AUTOSAR XML (schema 4-0-3)
standard types defined: Boolean, UInt16
package /AUTOSAR_Platform/DataConstrs
  range DC_Boolean: raw 0..1
  range DC_UInt16: raw 0..65535
package /PATAC/MSM/ComponentTypes
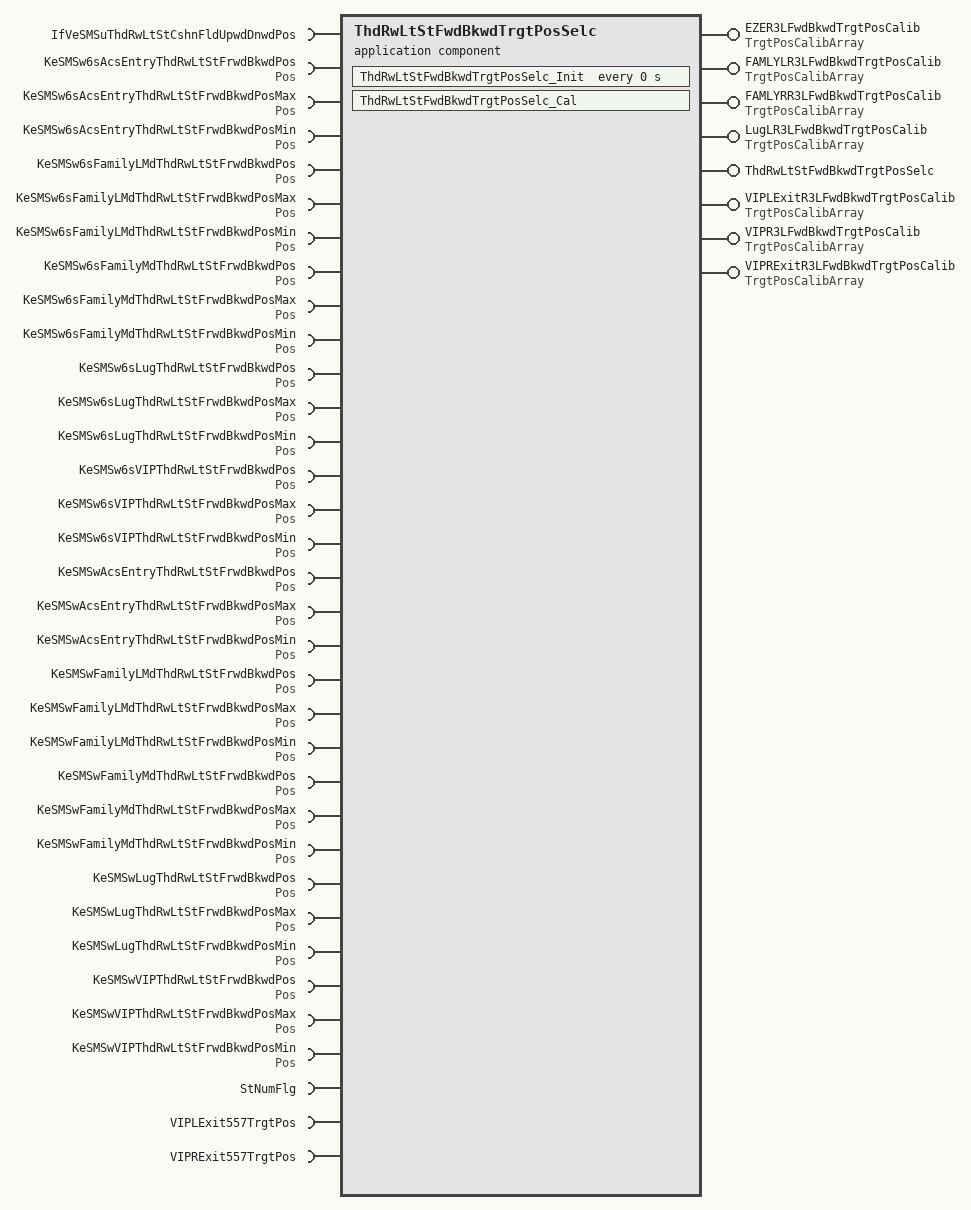
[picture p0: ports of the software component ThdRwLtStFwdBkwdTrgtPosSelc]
  application sw component type ThdRwLtStFwdBkwdTrgtPosSelc
    8 x provide port:
      EZER3LFwdBkwdTrgtPosCalib: nonqueued-sender-com-spec{data-element=TrgtPosArray, init-value=[4095, 4095, 4095]}, provided-interface=TrgtPosCalibArray
      FAMLYLR3LFwdBkwdTrgtPosCalib: nonqueued-sender-com-spec{data-element=TrgtPosArray, init-value=[4095, 4095, 4095]}, provided-interface=TrgtPosCalibArray
      FAMLYRR3LFwdBkwdTrgtPosCalib: nonqueued-sender-com-spec{data-element=TrgtPosArray, init-value=[4095, 4095, 4095]}, provided-interface=TrgtPosCalibArray
      LugLR3LFwdBkwdTrgtPosCalib: nonqueued-sender-com-spec{data-element=TrgtPosArray, init-value=[4095, 4095, 4095]}, provided-interface=TrgtPosCalibArray
      ThdRwLtStFwdBkwdTrgtPosSelc: server-com-spec{operation=Cal, queue-length=1}, provided-interface=ThdRwLtStFwdBkwdTrgtPosSelc
      VIPLExitR3LFwdBkwdTrgtPosCalib: nonqueued-sender-com-spec{data-element=TrgtPosArray, init-value=[4095, 4095, 4095]}, provided-interface=TrgtPosCalibArray
      VIPR3LFwdBkwdTrgtPosCalib: nonqueued-sender-com-spec{data-element=TrgtPosArray, init-value=[4095, 4095, 4095]}, provided-interface=TrgtPosCalibArray
      VIPRExitR3LFwdBkwdTrgtPosCalib: nonqueued-sender-com-spec{data-element=TrgtPosArray, init-value=[4095, 4095, 4095]}, provided-interface=TrgtPosCalibArray
    34 x require port:
      IfVeSMSuThdRwLtStCshnFldUpwdDnwdPos: nonqueued-receiver-com-spec{data-element=Val, filter=data-filter-type=ALWAYS, init-value=0}, required-interface=IfVeSMSuThdRwLtStCshnFldUpwdDnwdPos
      KeSMSw6sAcsEntryThdRwLtStFrwdBkwdPos: parameter-require-com-spec{init-value=2760, parameter=Val}, required-interface=Pos
      KeSMSw6sAcsEntryThdRwLtStFrwdBkwdPosMax: parameter-require-com-spec{init-value=4000, parameter=Val}, required-interface=Pos
      KeSMSw6sAcsEntryThdRwLtStFrwdBkwdPosMin: parameter-require-com-spec{init-value=2760, parameter=Val}, required-interface=Pos
      KeSMSw6sFamilyLMdThdRwLtStFrwdBkwdPos: parameter-require-com-spec{init-value=0, parameter=Val}, required-interface=Pos
      KeSMSw6sFamilyLMdThdRwLtStFrwdBkwdPosMax: parameter-require-com-spec{init-value=0, parameter=Val}, required-interface=Pos
      KeSMSw6sFamilyLMdThdRwLtStFrwdBkwdPosMin: parameter-require-com-spec{init-value=0, parameter=Val}, required-interface=Pos
      KeSMSw6sFamilyMdThdRwLtStFrwdBkwdPos: parameter-require-com-spec{init-value=0, parameter=Val}, required-interface=Pos
      KeSMSw6sFamilyMdThdRwLtStFrwdBkwdPosMax: parameter-require-com-spec{init-value=0, parameter=Val}, required-interface=Pos
      KeSMSw6sFamilyMdThdRwLtStFrwdBkwdPosMin: parameter-require-com-spec{init-value=0, parameter=Val}, required-interface=Pos
      KeSMSw6sLugThdRwLtStFrwdBkwdPos: parameter-require-com-spec{init-value=30, parameter=Val}, required-interface=Pos
      KeSMSw6sLugThdRwLtStFrwdBkwdPosMax: parameter-require-com-spec{init-value=40, parameter=Val}, required-interface=Pos
      KeSMSw6sLugThdRwLtStFrwdBkwdPosMin: parameter-require-com-spec{init-value=20, parameter=Val}, required-interface=Pos
      KeSMSw6sVIPThdRwLtStFrwdBkwdPos: parameter-require-com-spec{init-value=4000, parameter=Val}, required-interface=Pos
      KeSMSw6sVIPThdRwLtStFrwdBkwdPosMax: parameter-require-com-spec{init-value=4000, parameter=Val}, required-interface=Pos
      KeSMSw6sVIPThdRwLtStFrwdBkwdPosMin: parameter-require-com-spec{init-value=4000, parameter=Val}, required-interface=Pos
      KeSMSwAcsEntryThdRwLtStFrwdBkwdPos: parameter-require-com-spec{init-value=2760, parameter=Val}, required-interface=Pos
      KeSMSwAcsEntryThdRwLtStFrwdBkwdPosMax: parameter-require-com-spec{init-value=4000, parameter=Val}, required-interface=Pos
      KeSMSwAcsEntryThdRwLtStFrwdBkwdPosMin: parameter-require-com-spec{init-value=2760, parameter=Val}, required-interface=Pos
      KeSMSwFamilyLMdThdRwLtStFrwdBkwdPos: parameter-require-com-spec{init-value=0, parameter=Val}, required-interface=Pos
      KeSMSwFamilyLMdThdRwLtStFrwdBkwdPosMax: parameter-require-com-spec{init-value=0, parameter=Val}, required-interface=Pos
      KeSMSwFamilyLMdThdRwLtStFrwdBkwdPosMin: parameter-require-com-spec{init-value=0, parameter=Val}, required-interface=Pos
      KeSMSwFamilyMdThdRwLtStFrwdBkwdPos: parameter-require-com-spec{init-value=0, parameter=Val}, required-interface=Pos
      KeSMSwFamilyMdThdRwLtStFrwdBkwdPosMax: parameter-require-com-spec{init-value=0, parameter=Val}, required-interface=Pos
      KeSMSwFamilyMdThdRwLtStFrwdBkwdPosMin: parameter-require-com-spec{init-value=0, parameter=Val}, required-interface=Pos
      KeSMSwLugThdRwLtStFrwdBkwdPos: parameter-require-com-spec{init-value=30, parameter=Val}, required-interface=Pos
      KeSMSwLugThdRwLtStFrwdBkwdPosMax: parameter-require-com-spec{init-value=40, parameter=Val}, required-interface=Pos
      KeSMSwLugThdRwLtStFrwdBkwdPosMin: parameter-require-com-spec{init-value=20, parameter=Val}, required-interface=Pos
      KeSMSwVIPThdRwLtStFrwdBkwdPos: parameter-require-com-spec{init-value=4000, parameter=Val}, required-interface=Pos
      KeSMSwVIPThdRwLtStFrwdBkwdPosMax: parameter-require-com-spec{init-value=4000, parameter=Val}, required-interface=Pos
      KeSMSwVIPThdRwLtStFrwdBkwdPosMin: parameter-require-com-spec{init-value=4000, parameter=Val}, required-interface=Pos
      StNumFlg: required-interface=StNumFlg
        required-com-specs:
          data-element=Is4s, filter=data-filter-type=ALWAYS, init-value=0
          data-element=Is6s, filter=data-filter-type=ALWAYS, init-value=0
          data-element=Is6s7s, filter=data-filter-type=ALWAYS, init-value=0
          data-element=Is7s, filter=data-filter-type=ALWAYS, init-value=0
      VIPLExit557TrgtPos: required-com-specs=[VIPLExit557TrgtPos/Get, VIPLExit557TrgtPos/Set], required-interface=VIPLExit557TrgtPos
      VIPRExit557TrgtPos: required-com-specs=[VIPRExit557TrgtPos/Get, VIPRExit557TrgtPos/Set], required-interface=VIPRExit557TrgtPos
    behavior ThdRwLtStFwdBkwdTrgtPosSelc_InternalBehavior
      operation invoked event OIT_ThdRwLtStFwdBkwdTrgtPosSelc_Cal_ThdRwLtStFwdBkwdTrgtPosSelc_Cal: start-on-event=ThdRwLtStFwdBkwdTrgtPosSelc_Cal, operation=ThdRwLtStFwdBkwdTrgtPosSelc.Cal
      timing event ThdRwLtStFwdBkwdTrgtPosSelc_InitEvent: start-on-event=ThdRwLtStFwdBkwdTrgtPosSelc_Init, period=0
      runnable ThdRwLtStFwdBkwdTrgtPosSelc_Cal
        data-receive-point-by-arguments:
          5 x access:
            REC_IfVeSMSuThdRwLtStCshnFldUpwdDnwdPos_Val: accessed-variable=IfVeSMSuThdRwLtStCshnFldUpwdDnwdPos.Val
            REC_StNumFlg_Is4s: accessed-variable=StNumFlg.Is4s
            REC_StNumFlg_Is6s: accessed-variable=StNumFlg.Is6s
            REC_StNumFlg_Is6s7s: accessed-variable=StNumFlg.Is6s7s
            REC_StNumFlg_Is7s: accessed-variable=StNumFlg.Is7s
        data-send-points:
          7 x access:
            SEND_EZER3LFwdBkwdTrgtPosCalib_TrgtPosArray: accessed-variable=EZER3LFwdBkwdTrgtPosCalib.TrgtPosArray
            SEND_FAMLYLR3LFwdBkwdTrgtPosCalib_TrgtPosArray: accessed-variable=FAMLYLR3LFwdBkwdTrgtPosCalib.TrgtPosArray
            SEND_FAMLYRR3LFwdBkwdTrgtPosCalib_TrgtPosArray: accessed-variable=FAMLYRR3LFwdBkwdTrgtPosCalib.TrgtPosArray
            SEND_LugLR3LFwdBkwdTrgtPosCalib_TrgtPosArray: accessed-variable=LugLR3LFwdBkwdTrgtPosCalib.TrgtPosArray
            SEND_VIPLExitR3LFwdBkwdTrgtPosCalib_TrgtPosArray: accessed-variable=VIPLExitR3LFwdBkwdTrgtPosCalib.TrgtPosArray
            SEND_VIPR3LFwdBkwdTrgtPosCalib_TrgtPosArray: accessed-variable=VIPR3LFwdBkwdTrgtPosCalib.TrgtPosArray
            SEND_VIPRExitR3LFwdBkwdTrgtPosCalib_TrgtPosArray: accessed-variable=VIPRExitR3LFwdBkwdTrgtPosCalib.TrgtPosArray
        30 x parameter access:
          PA_KeSMSw6sAcsEntryThdRwLtStFrwdBkwdPos_Val: accessed-parameter=KeSMSw6sAcsEntryThdRwLtStFrwdBkwdPos.Val
          PA_KeSMSw6sAcsEntryThdRwLtStFrwdBkwdPosMax_Val: accessed-parameter=KeSMSw6sAcsEntryThdRwLtStFrwdBkwdPosMax.Val
          PA_KeSMSw6sAcsEntryThdRwLtStFrwdBkwdPosMin_Val: accessed-parameter=KeSMSw6sAcsEntryThdRwLtStFrwdBkwdPosMin.Val
          PA_KeSMSw6sFamilyLMdThdRwLtStFrwdBkwdPos_Val: accessed-parameter=KeSMSw6sFamilyLMdThdRwLtStFrwdBkwdPos.Val
          PA_KeSMSw6sFamilyLMdThdRwLtStFrwdBkwdPosMax_Val: accessed-parameter=KeSMSw6sFamilyLMdThdRwLtStFrwdBkwdPosMax.Val
          PA_KeSMSw6sFamilyLMdThdRwLtStFrwdBkwdPosMin_Val: accessed-parameter=KeSMSw6sFamilyLMdThdRwLtStFrwdBkwdPosMin.Val
          PA_KeSMSw6sFamilyMdThdRwLtStFrwdBkwdPos_Val: accessed-parameter=KeSMSw6sFamilyMdThdRwLtStFrwdBkwdPos.Val
          PA_KeSMSw6sFamilyMdThdRwLtStFrwdBkwdPosMax_Val: accessed-parameter=KeSMSw6sFamilyMdThdRwLtStFrwdBkwdPosMax.Val
          PA_KeSMSw6sFamilyMdThdRwLtStFrwdBkwdPosMin_Val: accessed-parameter=KeSMSw6sFamilyMdThdRwLtStFrwdBkwdPosMin.Val
          PA_KeSMSw6sLugThdRwLtStFrwdBkwdPos_Val: accessed-parameter=KeSMSw6sLugThdRwLtStFrwdBkwdPos.Val
          PA_KeSMSw6sLugThdRwLtStFrwdBkwdPosMax_Val: accessed-parameter=KeSMSw6sLugThdRwLtStFrwdBkwdPosMax.Val
          PA_KeSMSw6sLugThdRwLtStFrwdBkwdPosMin_Val: accessed-parameter=KeSMSw6sLugThdRwLtStFrwdBkwdPosMin.Val
          PA_KeSMSw6sVIPThdRwLtStFrwdBkwdPos_Val: accessed-parameter=KeSMSw6sVIPThdRwLtStFrwdBkwdPos.Val
          PA_KeSMSw6sVIPThdRwLtStFrwdBkwdPosMax_Val: accessed-parameter=KeSMSw6sVIPThdRwLtStFrwdBkwdPosMax.Val
          PA_KeSMSw6sVIPThdRwLtStFrwdBkwdPosMin_Val: accessed-parameter=KeSMSw6sVIPThdRwLtStFrwdBkwdPosMin.Val
          PA_KeSMSwAcsEntryThdRwLtStFrwdBkwdPos_Val: accessed-parameter=KeSMSwAcsEntryThdRwLtStFrwdBkwdPos.Val
          PA_KeSMSwAcsEntryThdRwLtStFrwdBkwdPosMax_Val: accessed-parameter=KeSMSwAcsEntryThdRwLtStFrwdBkwdPosMax.Val
          PA_KeSMSwAcsEntryThdRwLtStFrwdBkwdPosMin_Val: accessed-parameter=KeSMSwAcsEntryThdRwLtStFrwdBkwdPosMin.Val
          PA_KeSMSwFamilyLMdThdRwLtStFrwdBkwdPos_Val: accessed-parameter=KeSMSwFamilyLMdThdRwLtStFrwdBkwdPos.Val
          PA_KeSMSwFamilyLMdThdRwLtStFrwdBkwdPosMax_Val: accessed-parameter=KeSMSwFamilyLMdThdRwLtStFrwdBkwdPosMax.Val
          PA_KeSMSwFamilyLMdThdRwLtStFrwdBkwdPosMin_Val: accessed-parameter=KeSMSwFamilyLMdThdRwLtStFrwdBkwdPosMin.Val
          PA_KeSMSwFamilyMdThdRwLtStFrwdBkwdPos_Val: accessed-parameter=KeSMSwFamilyMdThdRwLtStFrwdBkwdPos.Val
          PA_KeSMSwFamilyMdThdRwLtStFrwdBkwdPosMax_Val: accessed-parameter=KeSMSwFamilyMdThdRwLtStFrwdBkwdPosMax.Val
          PA_KeSMSwFamilyMdThdRwLtStFrwdBkwdPosMin_Val: accessed-parameter=KeSMSwFamilyMdThdRwLtStFrwdBkwdPosMin.Val
          PA_KeSMSwLugThdRwLtStFrwdBkwdPos_Val: accessed-parameter=KeSMSwLugThdRwLtStFrwdBkwdPos.Val
          PA_KeSMSwLugThdRwLtStFrwdBkwdPosMax_Val: accessed-parameter=KeSMSwLugThdRwLtStFrwdBkwdPosMax.Val
          PA_KeSMSwLugThdRwLtStFrwdBkwdPosMin_Val: accessed-parameter=KeSMSwLugThdRwLtStFrwdBkwdPosMin.Val
          PA_KeSMSwVIPThdRwLtStFrwdBkwdPos_Val: accessed-parameter=KeSMSwVIPThdRwLtStFrwdBkwdPos.Val
          PA_KeSMSwVIPThdRwLtStFrwdBkwdPosMax_Val: accessed-parameter=KeSMSwVIPThdRwLtStFrwdBkwdPosMax.Val
          PA_KeSMSwVIPThdRwLtStFrwdBkwdPosMin_Val: accessed-parameter=KeSMSwVIPThdRwLtStFrwdBkwdPosMin.Val
        sync call SC_VIPLExit557TrgtPos_Get: operation=VIPLExit557TrgtPos.Get, timeout=0
        sync call SC_VIPRExit557TrgtPos_Get: operation=VIPRExit557TrgtPos.Get, timeout=0
      runnable ThdRwLtStFwdBkwdTrgtPosSelc_Init
        30 x parameter access:
          PA_KeSMSw6sAcsEntryThdRwLtStFrwdBkwdPos_Val: accessed-parameter=KeSMSw6sAcsEntryThdRwLtStFrwdBkwdPos.Val
          PA_KeSMSw6sAcsEntryThdRwLtStFrwdBkwdPosMax_Val: accessed-parameter=KeSMSw6sAcsEntryThdRwLtStFrwdBkwdPosMax.Val
          PA_KeSMSw6sAcsEntryThdRwLtStFrwdBkwdPosMin_Val: accessed-parameter=KeSMSw6sAcsEntryThdRwLtStFrwdBkwdPosMin.Val
          PA_KeSMSw6sFamilyLMdThdRwLtStFrwdBkwdPos_Val: accessed-parameter=KeSMSw6sFamilyLMdThdRwLtStFrwdBkwdPos.Val
          PA_KeSMSw6sFamilyLMdThdRwLtStFrwdBkwdPosMax_Val: accessed-parameter=KeSMSw6sFamilyLMdThdRwLtStFrwdBkwdPosMax.Val
          PA_KeSMSw6sFamilyLMdThdRwLtStFrwdBkwdPosMin_Val: accessed-parameter=KeSMSw6sFamilyLMdThdRwLtStFrwdBkwdPosMin.Val
          PA_KeSMSw6sFamilyMdThdRwLtStFrwdBkwdPos_Val: accessed-parameter=KeSMSw6sFamilyMdThdRwLtStFrwdBkwdPos.Val
          PA_KeSMSw6sFamilyMdThdRwLtStFrwdBkwdPosMax_Val: accessed-parameter=KeSMSw6sFamilyMdThdRwLtStFrwdBkwdPosMax.Val
          PA_KeSMSw6sFamilyMdThdRwLtStFrwdBkwdPosMin_Val: accessed-parameter=KeSMSw6sFamilyMdThdRwLtStFrwdBkwdPosMin.Val
          PA_KeSMSw6sLugThdRwLtStFrwdBkwdPos_Val: accessed-parameter=KeSMSw6sLugThdRwLtStFrwdBkwdPos.Val
          PA_KeSMSw6sLugThdRwLtStFrwdBkwdPosMax_Val: accessed-parameter=KeSMSw6sLugThdRwLtStFrwdBkwdPosMax.Val
          PA_KeSMSw6sLugThdRwLtStFrwdBkwdPosMin_Val: accessed-parameter=KeSMSw6sLugThdRwLtStFrwdBkwdPosMin.Val
          PA_KeSMSw6sVIPThdRwLtStFrwdBkwdPos_Val: accessed-parameter=KeSMSw6sVIPThdRwLtStFrwdBkwdPos.Val
          PA_KeSMSw6sVIPThdRwLtStFrwdBkwdPosMax_Val: accessed-parameter=KeSMSw6sVIPThdRwLtStFrwdBkwdPosMax.Val
          PA_KeSMSw6sVIPThdRwLtStFrwdBkwdPosMin_Val: accessed-parameter=KeSMSw6sVIPThdRwLtStFrwdBkwdPosMin.Val
          PA_KeSMSwAcsEntryThdRwLtStFrwdBkwdPos_Val: accessed-parameter=KeSMSwAcsEntryThdRwLtStFrwdBkwdPos.Val
          PA_KeSMSwAcsEntryThdRwLtStFrwdBkwdPosMax_Val: accessed-parameter=KeSMSwAcsEntryThdRwLtStFrwdBkwdPosMax.Val
          PA_KeSMSwAcsEntryThdRwLtStFrwdBkwdPosMin_Val: accessed-parameter=KeSMSwAcsEntryThdRwLtStFrwdBkwdPosMin.Val
          PA_KeSMSwFamilyLMdThdRwLtStFrwdBkwdPos_Val: accessed-parameter=KeSMSwFamilyLMdThdRwLtStFrwdBkwdPos.Val
          PA_KeSMSwFamilyLMdThdRwLtStFrwdBkwdPosMax_Val: accessed-parameter=KeSMSwFamilyLMdThdRwLtStFrwdBkwdPosMax.Val
          PA_KeSMSwFamilyLMdThdRwLtStFrwdBkwdPosMin_Val: accessed-parameter=KeSMSwFamilyLMdThdRwLtStFrwdBkwdPosMin.Val
          PA_KeSMSwFamilyMdThdRwLtStFrwdBkwdPos_Val: accessed-parameter=KeSMSwFamilyMdThdRwLtStFrwdBkwdPos.Val
          PA_KeSMSwFamilyMdThdRwLtStFrwdBkwdPosMax_Val: accessed-parameter=KeSMSwFamilyMdThdRwLtStFrwdBkwdPosMax.Val
          PA_KeSMSwFamilyMdThdRwLtStFrwdBkwdPosMin_Val: accessed-parameter=KeSMSwFamilyMdThdRwLtStFrwdBkwdPosMin.Val
          PA_KeSMSwLugThdRwLtStFrwdBkwdPos_Val: accessed-parameter=KeSMSwLugThdRwLtStFrwdBkwdPos.Val
          PA_KeSMSwLugThdRwLtStFrwdBkwdPosMax_Val: accessed-parameter=KeSMSwLugThdRwLtStFrwdBkwdPosMax.Val
          PA_KeSMSwLugThdRwLtStFrwdBkwdPosMin_Val: accessed-parameter=KeSMSwLugThdRwLtStFrwdBkwdPosMin.Val
          PA_KeSMSwVIPThdRwLtStFrwdBkwdPos_Val: accessed-parameter=KeSMSwVIPThdRwLtStFrwdBkwdPos.Val
          PA_KeSMSwVIPThdRwLtStFrwdBkwdPosMax_Val: accessed-parameter=KeSMSwVIPThdRwLtStFrwdBkwdPosMax.Val
          PA_KeSMSwVIPThdRwLtStFrwdBkwdPosMin_Val: accessed-parameter=KeSMSwVIPThdRwLtStFrwdBkwdPosMin.Val
  swc implementation ThdRwLtStFwdBkwdTrgtPosSelc_Implementation: behavior=ThdRwLtStFwdBkwdTrgtPosSelc_InternalBehavior
    code-descriptors:
      code Default: artifact-descriptors=autosar-engineering-object={short-label=Default, category=SWSRC}
package /PATAC/MSM/ModeAdjust/CalPortInterface
  parameter interface Pos
    parameter data prototype Val: sw-calibration-access=READ-WRITE, type=UInt16
package /PATAC/MSM/ModeAdjust/DataType
  impl type TrgtPosCalibArray: category=ARRAY, sw-calibration-access=READ-ONLY, type-emitter=RTE  # 0:pos 1:max 2:min
    element Element: array-size=3, array-size-semantics=FIXED-SIZE, implementation-data-type=UInt16, invalid-value=0
package /PATAC/MSM/ModeAdjust/Interfaces
  sender receiver interface IfVeSMSuThdRwLtStCshnFldUpwdDnwdPos: invalidation-policy{data-element=Val, handle-invalid=DONT-INVALIDATE}
    data Val: type=UInt16
package /PATAC/MSM/ModeAdjust/PortInterface
  client server interface ThdRwLtStFwdBkwdTrgtPosSelc
    operation Cal
  client server interface VIPLExit557TrgtPos
    operation Get
      7 x arg, all with type=UInt16, direction=OUT, server-argument-impl-policy=USE-ARGUMENT-TYPE:
        SecRwLtStBkReclnTrgtPos
        SecRwLtStZeroTrgtPos
        SecRwLtStLgrstUpwdDnwdTrgtPos
        SecRwLtStLgrstInwdOtwdTrgtPos
        ThdRwLtStBkReclnTrgtPos
        ThdRwLtStFwdBkwdTrgtPos
        SecRwLtStFwdBkwdTrgtPos
    operation Set
  client server interface VIPRExit557TrgtPos
    operation Get
      11 x arg, all with type=UInt16, direction=OUT, server-argument-impl-policy=USE-ARGUMENT-TYPE:
        SecRwRtStBkReclnTrgtPos
        SecRwRtStZeroTrgtPos
        SecRwRtStLgrstUpwdDnwdTrgtPos
        SecRwRtStLgrstInwdOtwdTrgtPos
        ThdRwLtStBkReclnTrgtPos
        ThdRwLtStFwdBkwdTrgtPos
        ThdRwRtStBkReclnTrgtPos
        ThdRwRtStFwdBkwdTrgtPos
        PassStBkReclnTrgtPos
        PassStFwdBkwdTrgtPos
        SecRwRtStFwdBkwdTrgtPos
    operation Set
  sender receiver interface StNumFlg
    4 x data, all with type=Boolean:
      Is4s
      Is6s
      Is6s7s
      Is7s
    invalidation-policys:
      data-element=Is4s, handle-invalid=DONT-INVALIDATE
      data-element=Is6s, handle-invalid=DONT-INVALIDATE
      data-element=Is6s7s, handle-invalid=DONT-INVALIDATE
      data-element=Is7s, handle-invalid=DONT-INVALIDATE
  sender receiver interface TrgtPosCalibArray: invalidation-policy{data-element=TrgtPosArray, handle-invalid=DONT-INVALIDATE}
    data TrgtPosArray: type=TrgtPosCalibArray  # 0:Pos 1:Max 2:Min
